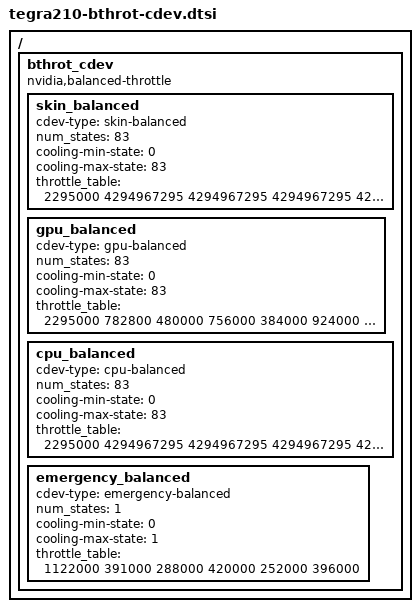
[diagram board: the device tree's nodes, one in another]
/*
 * arch/arm64/boot/dts/tegra210-platforms/tegra210-bthrot-cdev.dtsi
 *
 * Copyright (c) 2014, NVIDIA CORPORATION.  All rights reserved.
 *
 * This program is free software; you can redistribute it and/or modify
 * it under the terms of the GNU General Public License as published by
 * the Free Software Foundation; version 2 of the License.
 *
 * This program is distributed in the hope that it will be useful, but WITHOUT
 * ANY WARRANTY; without even the implied warranty of MERCHANTABILITY or
 * FITNESS FOR A PARTICULAR PURPOSE.  See the GNU General Public License for
 * more details.
 *
 * You should have received a copy of the GNU General Public License along
 * with this program; if not, write to the Free Software Foundation, Inc.,
 * 51 Franklin Street, Fifth Floor, Boston, MA  02110-1301, USA.
 *
 */

/{
	bthrot_cdev {
		compatible = "nvidia,balanced-throttle";
		skin_balanced {
			cdev-type = "skin-balanced";
			num_states = <83>;
			cooling-min-state = <0>;
			cooling-max-state = <83>;
			#cooling-cells = <2>;
			status = "okay";
			throttle_table = <
				/*CPU		GPU		C2BUS		C3BUS		SCLK		EMC	*/
				2295000		4294967295	4294967295	4294967295	4294967295	4294967295
				2269500		4294967295	4294967295	4294967295	4294967295	4294967295
				2244000		4294967295	4294967295	4294967295	4294967295	4294967295
				2218500		4294967295	4294967295	4294967295	4294967295	4294967295
				2193000		4294967295	4294967295	4294967295	4294967295	4294967295
				2167500		4294967295	4294967295	4294967295	4294967295	4294967295
				2142000		4294967295	4294967295	4294967295	4294967295	4294967295
				2116500		4294967295	4294967295	4294967295	4294967295	4294967295
				2091000		4294967295	4294967295	4294967295	4294967295	4294967295
				2065500		4294967295	4294967295	4294967295	4294967295	4294967295
				2040000		4294967295	4294967295	4294967295	4294967295	4294967295
				2014500		4294967295	4294967295	4294967295	4294967295	4294967295
				1989000		4294967295	4294967295	4294967295	4294967295	4294967295
				1963500		4294967295	4294967295	4294967295	4294967295	4294967295
				1938000		4294967295	4294967295	4294967295	4294967295	4294967295
				1912500		4294967295	4294967295	4294967295	4294967295	4294967295
				1887000		4294967295	4294967295	4294967295	4294967295	4294967295
				1861500		4294967295	4294967295	4294967295	4294967295	4294967295
				1836000		4294967295	4294967295	4294967295	4294967295	4294967295
				1810500		4294967295	4294967295	4294967295	4294967295	4294967295
				1785000		4294967295	4294967295	4294967295	4294967295	4294967295
				1759500		4294967295	4294967295	4294967295	4294967295	4294967295
				1734000		4294967295	4294967295	4294967295	4294967295	4294967295
				1708500		4294967295	4294967295	4294967295	4294967295	4294967295
				1683000		4294967295	4294967295	4294967295	4294967295	4294967295
				1657500		4294967295	4294967295	4294967295	4294967295	4294967295
				1632000		4294967295	4294967295	4294967295	4294967295	4294967295
				1606500		790000		4294967295	4294967295	4294967295	4294967295
				1581000		776000		4294967295	4294967295	4294967295	4294967295
				1555500		762000		4294967295	4294967295	4294967295	4294967295
				1530000		749000		4294967295	4294967295	4294967295	4294967295
				1504500		735000		4294967295	4294967295	4294967295	4294967295
				1479000		721000		4294967295	4294967295	4294967295	4294967295
				1453500		707000		4294967295	4294967295	4294967295	4294967295
				1428000		693000		4294967295	4294967295	4294967295	4294967295
				1402500		679000		4294967295	4294967295	4294967295	4294967295
				1377000		666000		4294967295	4294967295	4294967295	4294967295
				1351500		652000		4294967295	4294967295	4294967295	4294967295
				1326000		638000		4294967295	4294967295	4294967295	4294967295
				1300500		624000		4294967295	4294967295	4294967295	4294967295
				1275000		610000		4294967295	4294967295	4294967295	4294967295
				1249500		596000		4294967295	4294967295	4294967295	4294967295
				1224000		582000		4294967295	4294967295	4294967295	792000
				1198500		569000		4294967295	4294967295	4294967295	792000
				1173000		555000		4294967295	4294967295	360000		792000
				1147500		541000		4294967295	4294967295	360000		792000
				1122000		527000		4294967295	684000		360000		792000
				1096500		513000		444000		684000		360000		792000
				1071000		499000		444000		684000		360000		792000
				1045500		486000		444000		684000		360000		792000
				1020000		472000		444000		684000		324000		792000
				994500		458000		444000		684000		324000		792000
				969000		444000		444000		600000		324000		792000
				943500		430000		444000		600000		324000		792000
				918000		416000		396000		600000		324000		792000
				892500		402000		396000		600000		324000		792000
				867000		389000		396000		600000		324000		792000
				841500		375000		396000		600000		288000		792000
				816000		361000		396000		600000		288000		792000
				790500		347000		396000		600000		288000		792000
				765000		333000		396000		504000		288000		792000
				739500		319000		348000		504000		288000		792000
				714000		306000		348000		504000		288000		624000
				688500		292000		348000		504000		288000		624000
				663000		278000		348000		504000		288000		624000
				637500		264000		348000		504000		288000		624000
				612000		250000		348000		504000		252000		624000
				586500		236000		348000		504000		252000		624000
				561000		222000		348000		420000		252000		624000
				535500		209000		288000		420000		252000		624000
				510000		195000		288000		420000		252000		624000
				484500		181000		288000		420000		252000		624000
				459000		167000		288000		420000		252000		624000
				433500		153000		288000		420000		252000		396000
				408000		139000		288000		420000		252000		396000
				382500		126000		288000		420000		252000		396000
				357000		112000		288000		420000		252000		396000
				331500		 98000		288000		420000		252000		396000
				306000		 84000		288000		420000		252000		396000
				280500		 84000		288000		420000		252000		396000
				255000		 84000		288000		420000		252000		396000
				229500		 84000		288000		420000		252000		396000
				204000		 84000		288000		420000		252000		396000
			>;
		};
		gpu_balanced {
			cdev-type = "gpu-balanced";
			num_states = <83>;
			cooling-min-state = <0>;
			cooling-max-state = <83>;
			#cooling-cells = <2>;
			status = "okay";
			throttle_table = <
				/*CPU		GPU		C2BUS		C3BUS		SCLK		EMC	*/
				2295000		782800		480000		756000		384000		924000
	  			2269500		772200		480000		756000		384000		924000
	  			2244000		761600		480000		756000		384000		924000
	  			2218500		751100		480000		756000		384000		924000
	  			2193000		740500		480000		756000		384000		924000
	  			2167500		729900		480000		756000		384000		924000
	  			2142000		719300		480000		756000		384000		924000
	  			2116500		708700		480000		756000		384000		924000
	  			2091000		698100		480000		756000		384000		924000
	  			2065500		687500		480000		756000		384000		924000
	  			2040000		676900		480000		756000		384000		924000
	  			2014500		666000		480000		756000		384000		924000
	  			1989000		656000		480000		756000		384000		924000
	  			1963500		645000		480000		756000		384000		924000
	  			1938000		635000		480000		756000		384000		924000
	  			1912500		624000		480000		756000		384000		924000
	  			1887000		613000		480000		756000		384000		924000
	  			1861500		603000		480000		756000		384000		924000
	  			1836000		592000		480000		756000		384000		924000
	  			1810500		582000		480000		756000		384000		924000
	  			1785000		571000		480000		756000		384000		924000
	  			1759500		560000		480000		756000		384000		924000
	  			1734000		550000		480000		756000		384000		924000
	  			1708500		539000		480000		756000		384000		924000
	  			1683000		529000		480000		756000		384000		924000
	  			1657500		518000		480000		756000		384000		924000
	  			1632000		508000		480000		756000		384000		924000
	  			1606500		497000		480000		756000		384000		924000
	  			1581000		486000		480000		756000		384000		924000
	  			1555500		476000		480000		756000		384000		924000
	  			1530000		465000		480000		756000		384000		924000
	  			1504500		455000		480000		756000		384000		924000
	  			1479000		444000		480000		756000		384000		924000
	  			1453500		433000		480000		756000		384000		924000
	  			1428000		423000		480000		756000		384000		924000
	  			1402500		412000		480000		756000		384000		924000
	  			1377000		402000		480000		756000		384000		924000
	  			1351500		391000		480000		756000		384000		924000
	  			1326000		380000		480000		756000		384000		924000
	  			1300500		370000		480000		756000		384000		924000
	  			1275000		359000		480000		756000		384000		924000
	  			1249500		349000		480000		756000		384000		924000
	  			1224000		338000		480000		756000		384000		792000
	  			1198500		328000		480000		756000		384000		792000
	  			1173000		317000		480000		756000		360000		792000
	  			1147500		306000		480000		756000		360000		792000
	  			1122000		296000		480000		684000		360000		792000
	  			1096500		285000		444000		684000		360000		792000
	  			1071000		275000		444000		684000		360000		792000
	  			1045500		264000		444000		684000		360000		792000
	  			1020000		253000		444000		684000		324000		792000
	  			994500		243000		444000		684000		324000		792000
	  			969000		232000		444000		600000		324000		792000
	  			943500		222000		444000		600000		324000		792000
	  			918000		211000		396000		600000		324000		792000
	  			892500		200000		396000		600000		324000		792000
	  			867000		190000		396000		600000		324000		792000
	  			841500		179000		396000		600000		288000		792000
	  			816000		169000		396000		600000		288000		792000
	  			790500		158000		396000		600000		288000		792000
	  			765000		148000		396000		504000		288000		792000
	  			739500		137000		348000		504000		288000		792000
	  			714000		126000		348000		504000		288000		624000
	  			688500		116000		348000		504000		288000		624000
	  			663000		105000		348000		504000		288000		624000
	  			637500		 95000		348000		504000		288000		624000
	  			612000		 84000		348000		504000		252000		624000
	  			586500		 84000		348000		504000		252000		624000
	  			561000		 84000		348000		420000		252000		624000
	  			535500		 84000		288000		420000		252000		624000
	  			510000		 84000		288000		420000		252000		624000
	  			484500		 84000		288000		420000		252000		624000
	  			459000		 84000		288000		420000		252000		624000
	  			433500		 84000		288000		420000		252000		396000
	  			408000		 84000		288000		420000		252000		396000
	  			382500		 84000		288000		420000		252000		396000
	  			357000		 84000		288000		420000		252000		396000
	  			331500		 84000		288000		420000		252000		396000
	  			306000		 84000		288000		420000		252000		396000
	  			280500		 84000		288000		420000		252000		396000
	  			255000		 84000		288000		420000		252000		396000
	  			229500		 84000		288000		420000		252000		396000
	  			204000		 84000		288000		420000		252000		396000
			>;
		};
		cpu_balanced {
			cdev-type = "cpu-balanced";
			num_states = <83>;
			cooling-min-state = <0>;
			cooling-max-state = <83>;
			#cooling-cells = <2>;
			status = "okay";
			throttle_table = <
				/*CPU		GPU		C2BUS		C3BUS		SCLK		EMC	*/
				2295000		4294967295	4294967295	4294967295	4294967295	4294967295
				2269500		4294967295	4294967295	4294967295	4294967295	4294967295
				2244000		4294967295	4294967295	4294967295	4294967295	4294967295
				2218500		4294967295	4294967295	4294967295	4294967295	4294967295
				2193000		4294967295	4294967295	4294967295	4294967295	4294967295
				2167500		4294967295	4294967295	4294967295	4294967295	4294967295
				2142000		4294967295	4294967295	4294967295	4294967295	4294967295
				2116500		4294967295	4294967295	4294967295	4294967295	4294967295
				2091000		4294967295	4294967295	4294967295	4294967295	4294967295
				2065500		4294967295	4294967295	4294967295	4294967295	4294967295
				2040000		4294967295	4294967295	4294967295	4294967295	4294967295
				2014500		4294967295	4294967295	4294967295	4294967295	4294967295
				1989000		4294967295	4294967295	4294967295	4294967295	4294967295
				1963500		4294967295	4294967295	4294967295	4294967295	4294967295
				1938000		4294967295	4294967295	4294967295	4294967295	4294967295
				1912500		4294967295	4294967295	4294967295	4294967295	4294967295
				1887000		4294967295	4294967295	4294967295	4294967295	4294967295
				1861500		4294967295	4294967295	4294967295	4294967295	4294967295
				1836000		4294967295	4294967295	4294967295	4294967295	4294967295
				1810500		4294967295	4294967295	4294967295	4294967295	4294967295
				1785000		4294967295	4294967295	4294967295	4294967295	4294967295
				1759500		4294967295	4294967295	4294967295	4294967295	4294967295
				1734000		4294967295	4294967295	4294967295	4294967295	4294967295
				1708500		4294967295	4294967295	4294967295	4294967295	4294967295
				1683000		4294967295	4294967295	4294967295	4294967295	4294967295
				1657500		4294967295	4294967295	4294967295	4294967295	4294967295
				1632000		4294967295	4294967295	4294967295	4294967295	4294967295
				1606500		790000		4294967295	4294967295	4294967295	4294967295
				1581000		776000		4294967295	4294967295	4294967295	4294967295
				1555500		762000		4294967295	4294967295	4294967295	4294967295
				1530000		749000		4294967295	4294967295	4294967295	4294967295
				1504500		735000		4294967295	4294967295	4294967295	4294967295
				1479000		721000		4294967295	4294967295	4294967295	4294967295
				1453500		707000		4294967295	4294967295	4294967295	4294967295
				1428000		693000		4294967295	4294967295	4294967295	4294967295
				1402500		679000		4294967295	4294967295	4294967295	4294967295
				1377000		666000		4294967295	4294967295	4294967295	4294967295
				1351500		652000		4294967295	4294967295	4294967295	4294967295
				1326000		638000		4294967295	4294967295	4294967295	4294967295
				1300500		624000		4294967295	4294967295	4294967295	4294967295
				1275000		610000		4294967295	4294967295	4294967295	4294967295
				1249500		596000		4294967295	4294967295	4294967295	4294967295
				1224000		582000		4294967295	4294967295	4294967295	792000
				1198500		569000		4294967295	4294967295	4294967295	792000
				1173000		555000		4294967295	4294967295	360000		792000
				1147500		541000		4294967295	4294967295	360000		792000
				1122000		527000		4294967295	684000		360000		792000
				1096500		513000		444000		684000		360000		792000
				1071000		499000		444000		684000		360000		792000
				1045500		486000		444000		684000		360000		792000
				1020000		472000		444000		684000		324000		792000
				994500		458000		444000		684000		324000		792000
				969000		444000		444000		600000		324000		792000
				943500		430000		444000		600000		324000		792000
				918000		416000		396000		600000		324000		792000
				892500		402000		396000		600000		324000		792000
				867000		389000		396000		600000		324000		792000
				841500		375000		396000		600000		288000		792000
				816000		361000		396000		600000		288000		792000
				790500		347000		396000		600000		288000		792000
				765000		333000		396000		504000		288000		792000
				739500		319000		348000		504000		288000		792000
				714000		306000		348000		504000		288000		624000
				688500		292000		348000		504000		288000		624000
				663000		278000		348000		504000		288000		624000
				637500		264000		348000		504000		288000		624000
				612000		250000		348000		504000		252000		624000
				586500		236000		348000		504000		252000		624000
				561000		222000		348000		420000		252000		624000
				535500		209000		288000		420000		252000		624000
				510000		195000		288000		420000		252000		624000
				484500		181000		288000		420000		252000		624000
				459000		167000		288000		420000		252000		624000
				433500		153000		288000		420000		252000		396000
				408000		139000		288000		420000		252000		396000
				382500		126000		288000		420000		252000		396000
				357000		112000		288000		420000		252000		396000
				331500		 98000		288000		420000		252000		396000
				306000		 84000		288000		420000		252000		396000
				280500		 84000		288000		420000		252000		396000
				255000		 84000		288000		420000		252000		396000
				229500		 84000		288000		420000		252000		396000
				204000		 84000		288000		420000		252000		396000
			>;
		};
		emergency_balanced {
			cdev-type = "emergency-balanced";
			num_states = <1>;
			cooling-min-state = <0>;
			cooling-max-state = <1>;
			#cooling-cells = <2>;
			status = "okay";
			throttle_table = <
				/*CPU		GPU		C2BUS		C3BUS		SCLK		EMC	*/
				1122000		391000		288000		420000		252000		396000
			>;
		};
	};
};
